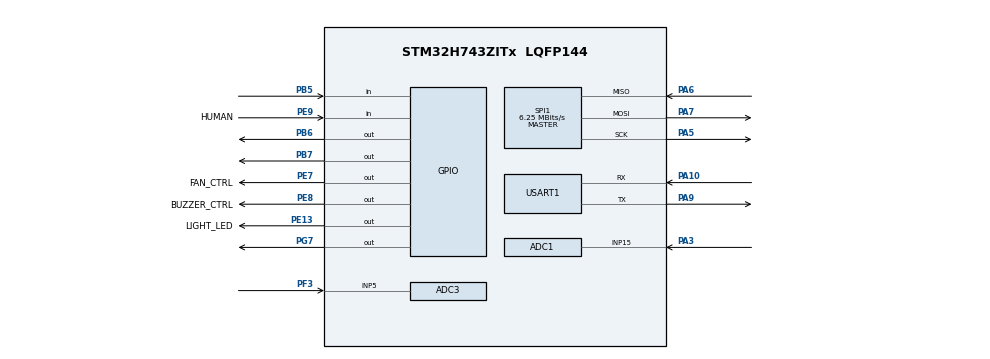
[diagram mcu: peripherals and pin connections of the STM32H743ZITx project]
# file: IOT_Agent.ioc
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ADC1.Channel-0\#ChannelRegularConversion=ADC_CHANNEL_15
ADC1.NbrOfConversionFlag=1
ADC1.OffsetNumber-0\#ChannelRegularConversion=ADC_OFFSET_NONE
ADC1.OffsetSignedSaturation-0\#ChannelRegularConversion=DISABLE
ADC1.Overrun=ADC_OVR_DATA_OVERWRITTEN
ADC1.Rank-0\#ChannelRegularConversion=1
ADC1.Resolution=ADC_RESOLUTION_12B
ADC1.SamplingTime-0\#ChannelRegularConversion=ADC_SAMPLETIME_387CYCLES_5
ADC1.master=1
ADC3.Channel-0\#ChannelRegularConversion=ADC_CHANNEL_5
ADC3.NbrOfConversionFlag=1
ADC3.OffsetNumber-0\#ChannelRegularConversion=ADC_OFFSET_NONE
ADC3.OffsetSignedSaturation-0\#ChannelRegularConversion=DISABLE
ADC3.Rank-0\#ChannelRegularConversion=1
ADC3.Resolution=ADC_RESOLUTION_12B_OPT
ADC3.SamplingTime-0\#ChannelRegularConversion=ADC_SAMPLETIME_1CYCLE_5
CORTEX_M7.default_mode_Activation=1
Mcu.Family=STM32H7
Mcu.Name=STM32H743ZITx
Mcu.Package=LQFP144
NVIC.PriorityGroup=NVIC_PRIORITYGROUP_4
NVIC.TIM6_DAC_IRQn=true\:1\:0\:true\:false\:true\:false\:true\:true
NVIC.TimeBase=TIM6_DAC_IRQn
NVIC.TimeBaseIP=TIM6
NVIC.USART1_IRQn=true\:6\:0\:true\:false\:true\:true\:true\:true
PA10.Mode=Asynchronous
PA10.Signal=USART1_RX
PA3.Signal=ADCx_INP15
PA5.Mode=Full_Duplex_Master
PA5.Signal=SPI1_SCK
PA6.Mode=Full_Duplex_Master
PA6.Signal=SPI1_MISO
PA7.Mode=Full_Duplex_Master
PA7.Signal=SPI1_MOSI
PA9.Mode=Asynchronous
PA9.Signal=USART1_TX
PB5.GPIO_PuPd=GPIO_PULLUP
PB5.Signal=GPIO_Input
PB6.GPIO_PuPd=GPIO_NOPULL
PB6.PinState=GPIO_PIN_SET
PB6.Signal=GPIO_Output
PB7.GPIO_PuPd=GPIO_NOPULL
PB7.PinState=GPIO_PIN_SET
PB7.Signal=GPIO_Output
PE13.GPIO_Label=LIGHT_LED
PE13.PinState=GPIO_PIN_SET
PE13.Signal=GPIO_Output
PE7.GPIO_Label=FAN_CTRL
PE7.Signal=GPIO_Output
PE8.GPIO_Label=BUZZER_CTRL
PE8.Signal=GPIO_Output
PE9.GPIO_Label=HUMAN
PE9.Signal=GPIO_Input
PF3.Mode=IN5-Single-Ended
PF3.Signal=ADC3_INP5
PG7.Signal=GPIO_Output
PH0-OSC_IN\ (PH0).Mode=HSE-External-Oscillator
PH0-OSC_IN\ (PH0).Signal=RCC_OSC_IN
PH1-OSC_OUT\ (PH1).Mode=HSE-External-Oscillator
PH1-OSC_OUT\ (PH1).Signal=RCC_OSC_OUT
ProjectManager.HeapSize=0x200
ProjectManager.StackSize=0x400
ProjectManager.TargetToolchain=MDK-ARM V5.32
RCC.ADCFreq_Value=75000000
RCC.APB1Freq_Value=100000000
RCC.APB2Freq_Value=100000000
RCC.APB3Freq_Value=100000000
RCC.APB4Freq_Value=100000000
RCC.CortexFreq_Value=400000000
RCC.D1PPRE=RCC_APB3_DIV2
RCC.D2PPRE1=RCC_APB1_DIV2
RCC.D2PPRE2=RCC_APB2_DIV2
RCC.D3PPRE=RCC_APB4_DIV2
RCC.DIVM1=2
RCC.DIVM2=2
RCC.DIVN1=64
RCC.DIVN2=12
RCC.DIVQ1=4
RCC.HCLKFreq_Value=200000000
RCC.HPRE=RCC_HCLK_DIV2
RCC.PLL2FRACN=0
RCC.PLL3FRACN=0
RCC.PLLFRACN=0
RCC.PLLSourceVirtual=RCC_PLLSOURCE_HSE
RCC.SYSCLKFreq_VALUE=400000000
RCC.SYSCLKSource=RCC_SYSCLKSOURCE_PLLCLK
RCC.USBFreq_Value=200000000
SH.ADCx_INP15.0=ADC1_INP15,IN15-Single-Ended
SPI1.BaudRatePrescaler=SPI_BAUDRATEPRESCALER_32
SPI1.CalculateBaudRate=6.25 MBits/s
SPI1.DataSize=SPI_DATASIZE_8BIT
SPI1.Direction=SPI_DIRECTION_2LINES
SPI1.Mode=SPI_MODE_MASTER
SPI1.VirtualType=VM_MASTER
USART1.VirtualMode-Asynchronous=VM_ASYNC
VP_SYS_VS_tim6.Mode=TIM6
board=custom

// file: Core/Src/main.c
/* USER CODE BEGIN Header */
/**
  ******************************************************************************
  * @file           : main.c
  * @brief          : Main program body
  ******************************************************************************
  * @attention
  *
  * Copyright (c) 2026 STMicroelectronics.
  * All rights reserved.
  *
  * This software is licensed under terms that can be found in the LICENSE file
  * in the root directory of this software component.
  * If no LICENSE file comes with this software, it is provided AS-IS.
  *
  ******************************************************************************
  */
/* USER CODE END Header */
#include "main.h"
#include "adc.h"
#include "spi.h"
#include "usart.h"
#include "gpio.h"

/* USER CODE BEGIN Includes */
#include <stdio.h>
#include "FreeRTOS_Demo.h"

/* USER CODE END Includes */

void SystemClock_Config(void);
void PeriphCommonClock_Config(void);
static void MPU_Config(void);

/* USER CODE BEGIN 0 */
int fputc(int ch, FILE *f)
{
    HAL_UART_Transmit(&huart1, (uint8_t *)&ch, 1, HAL_MAX_DELAY);
    return ch;
}
/* USER CODE END 0 */

int main(void)
{

  /* MPU Configuration--------------------------------------------------------*/
  MPU_Config();

  /* MCU Configuration--------------------------------------------------------*/

  /* Reset of all peripherals, Initializes the Flash interface and the Systick. */
  HAL_Init();

  /* Configure the system clock */
  SystemClock_Config();

/* Configure the peripherals common clocks */
  PeriphCommonClock_Config();

  /* Initialize all configured peripherals */
  MX_GPIO_Init();
  MX_SPI1_Init();
  MX_USART1_UART_Init();
  MX_ADC1_Init();
  MX_ADC3_Init();
  /* USER CODE BEGIN 2 */
  printf("h743 boot ok\r\n");

  if (uart_command_receive_start() != HAL_OK)
  {
    printf("USART1 RX start failed\r\n");
    Error_Handler();
  }

  printf("USART1 command RX ready\r\n");
  freertos_start();
  /* USER CODE END 2 */

  /* Infinite loop */
  /* USER CODE BEGIN WHILE */
  while (1)
  {
    HAL_GPIO_TogglePin(GPIOG, GPIO_PIN_7);
    HAL_Delay(500);
    /* USER CODE END WHILE */

  }
}

void SystemClock_Config(void)
{
  RCC_OscInitTypeDef RCC_OscInitStruct = {0};
  RCC_ClkInitTypeDef RCC_ClkInitStruct = {0};

  /** Supply configuration update enable
  */
  HAL_PWREx_ConfigSupply(PWR_LDO_SUPPLY);

  /** Configure the main internal regulator output voltage
  */
  __HAL_PWR_VOLTAGESCALING_CONFIG(PWR_REGULATOR_VOLTAGE_SCALE1);

  while(!__HAL_PWR_GET_FLAG(PWR_FLAG_VOSRDY)) {}

  /** Initializes the RCC Oscillators according to the specified parameters
  * in the RCC_OscInitTypeDef structure.
  */
  RCC_OscInitStruct.OscillatorType = RCC_OSCILLATORTYPE_HSE;
  RCC_OscInitStruct.HSEState = RCC_HSE_ON;
  RCC_OscInitStruct.PLL.PLLState = RCC_PLL_ON;
  RCC_OscInitStruct.PLL.PLLSource = RCC_PLLSOURCE_HSE;
  RCC_OscInitStruct.PLL.PLLM = 2;
  RCC_OscInitStruct.PLL.PLLN = 64;
  RCC_OscInitStruct.PLL.PLLP = 2;
  RCC_OscInitStruct.PLL.PLLQ = 4;
  RCC_OscInitStruct.PLL.PLLR = 2;
  RCC_OscInitStruct.PLL.PLLRGE = RCC_PLL1VCIRANGE_3;
  RCC_OscInitStruct.PLL.PLLVCOSEL = RCC_PLL1VCOWIDE;
  RCC_OscInitStruct.PLL.PLLFRACN = 0;
  if (HAL_RCC_OscConfig(&RCC_OscInitStruct) != HAL_OK)
  {
    Error_Handler();
  }

  /** Initializes the CPU, AHB and APB buses clocks
  */
  RCC_ClkInitStruct.ClockType = RCC_CLOCKTYPE_HCLK|RCC_CLOCKTYPE_SYSCLK
                              |RCC_CLOCKTYPE_PCLK1|RCC_CLOCKTYPE_PCLK2
                              |RCC_CLOCKTYPE_D3PCLK1|RCC_CLOCKTYPE_D1PCLK1;
  RCC_ClkInitStruct.SYSCLKSource = RCC_SYSCLKSOURCE_PLLCLK;
  RCC_ClkInitStruct.SYSCLKDivider = RCC_SYSCLK_DIV1;
  RCC_ClkInitStruct.AHBCLKDivider = RCC_HCLK_DIV2;
  RCC_ClkInitStruct.APB3CLKDivider = RCC_APB3_DIV2;
  RCC_ClkInitStruct.APB1CLKDivider = RCC_APB1_DIV2;
  RCC_ClkInitStruct.APB2CLKDivider = RCC_APB2_DIV2;
  RCC_ClkInitStruct.APB4CLKDivider = RCC_APB4_DIV2;

  if (HAL_RCC_ClockConfig(&RCC_ClkInitStruct, FLASH_LATENCY_2) != HAL_OK)
  {
    Error_Handler();
  }
}

void PeriphCommonClock_Config(void)
{
  RCC_PeriphCLKInitTypeDef PeriphClkInitStruct = {0};

  /** Initializes the peripherals clock
  */
  PeriphClkInitStruct.PeriphClockSelection = RCC_PERIPHCLK_ADC;
  PeriphClkInitStruct.PLL2.PLL2M = 2;
  PeriphClkInitStruct.PLL2.PLL2N = 12;
  PeriphClkInitStruct.PLL2.PLL2P = 2;
  PeriphClkInitStruct.PLL2.PLL2Q = 2;
  PeriphClkInitStruct.PLL2.PLL2R = 2;
  PeriphClkInitStruct.PLL2.PLL2RGE = RCC_PLL2VCIRANGE_3;
  PeriphClkInitStruct.PLL2.PLL2VCOSEL = RCC_PLL2VCOMEDIUM;
  PeriphClkInitStruct.PLL2.PLL2FRACN = 0;
  PeriphClkInitStruct.AdcClockSelection = RCC_ADCCLKSOURCE_PLL2;
  if (HAL_RCCEx_PeriphCLKConfig(&PeriphClkInitStruct) != HAL_OK)
  {
    Error_Handler();
  }
}

 /* MPU Configuration */

void MPU_Config(void)
{
  MPU_Region_InitTypeDef MPU_InitStruct = {0};

  /* Disables the MPU */
  HAL_MPU_Disable();

  /** Initializes and configures the Region and the memory to be protected
  */
  MPU_InitStruct.Enable = MPU_REGION_ENABLE;
  MPU_InitStruct.Number = MPU_REGION_NUMBER0;
  MPU_InitStruct.BaseAddress = 0x0;
  MPU_InitStruct.Size = MPU_REGION_SIZE_4GB;
  MPU_InitStruct.SubRegionDisable = 0x87;
  MPU_InitStruct.TypeExtField = MPU_TEX_LEVEL0;
  MPU_InitStruct.AccessPermission = MPU_REGION_NO_ACCESS;
  MPU_InitStruct.DisableExec = MPU_INSTRUCTION_ACCESS_DISABLE;
  MPU_InitStruct.IsShareable = MPU_ACCESS_SHAREABLE;
  MPU_InitStruct.IsCacheable = MPU_ACCESS_NOT_CACHEABLE;
  MPU_InitStruct.IsBufferable = MPU_ACCESS_NOT_BUFFERABLE;

  HAL_MPU_ConfigRegion(&MPU_InitStruct);
  /* Enables the MPU */
  HAL_MPU_Enable(MPU_PRIVILEGED_DEFAULT);

}

void HAL_TIM_PeriodElapsedCallback(TIM_HandleTypeDef *htim)
{
  if (htim->Instance == TIM6) {
    HAL_IncTick();
  }
}

void Error_Handler(void)
{
  __disable_irq();
  while (1)
  {
  }
}
